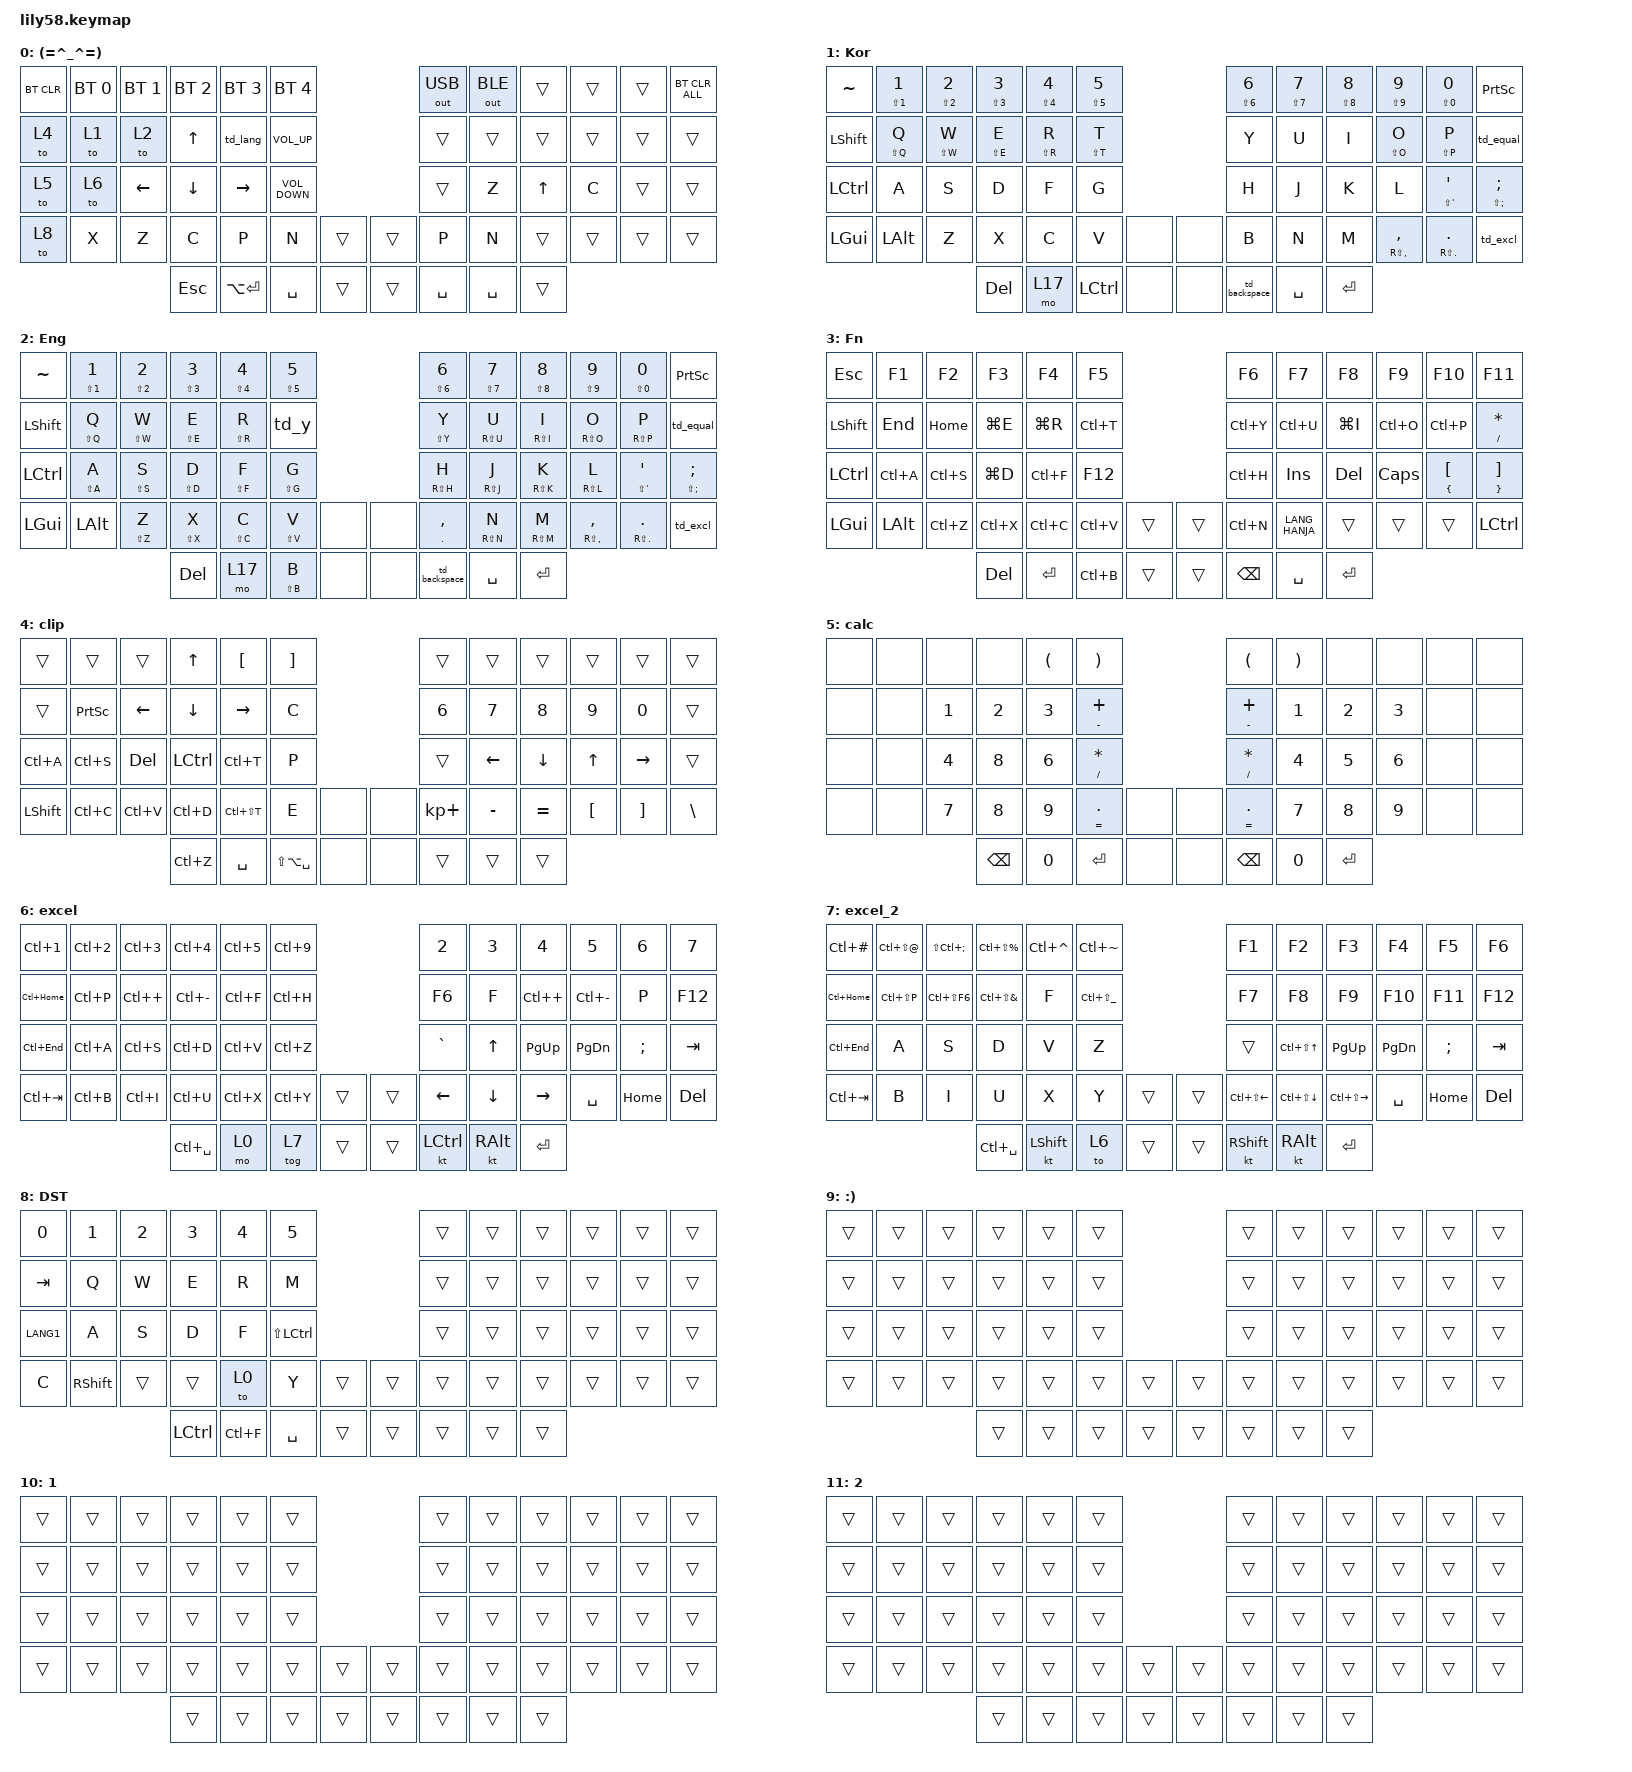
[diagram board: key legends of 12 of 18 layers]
/*
 * Copyright (c) 2020 The ZMK Contributors
 *
 * SPDX-License-Identifier: MIT
 */

#include <behaviors.dtsi>
#include <dt-bindings/zmk/bt.h>
#include <dt-bindings/zmk/keys.h>
#include <dt-bindings/zmk/outputs.h>

/ {
    combos {
        compatible = "zmk,combos";

        ctrl_c {
            bindings = <&kp LC(C)>;
            key-positions = <39 40>;
            timeout-ms = <50>;
        };

        ctrl_v {
            bindings = <&kp LC(V)>;
            key-positions = <39 41>;
            timeout-ms = <50>;
        };

        function {
            bindings = <&sl 3>;
            key-positions = <55 20>;
        };

        calc {
            bindings = <&tog 5>;
            key-positions = <26 28>;
        };

        excel {
            bindings = <&tog 6>;
            key-positions = <52 56>;
        };

        lang {
            bindings = <&kor_layer>;
            key-positions = <28 27>;
            layers = <2 1>;
        };

        egg1 {
            bindings = <&to 10>;
            key-positions = <25 26 15 28 20 21>;
            layers = <2 1>;
        };

        egg2 {
            bindings = <&to 11>;
            key-positions = <40 44 46>;
            layers = <10>;
        };

        egg3 {
            bindings = <&egg3>;
            key-positions = <28 33>;
            layers = <11>;
        };

        egg4 {
            bindings = <&egg4>;
            key-positions = <18>;
            layers = <12>;
        };

        egg_final {
            bindings = <&to 9>;
            key-positions = <1 13 25 37 10 22 34 48>;
            layers = <13>;
        };

        ctrl_del {
            bindings = <&kp LC(DELETE)>;
            key-positions = <27 26>;
            layers = <4>;
        };

        ctrl_layer {
            bindings = <&kp LS(LCTRL)>;
            key-positions = <27 28>;
            layers = <4>;
        };

        th {
            bindings = <&the>;
            key-positions = <17 30>;
            layers = <2>;
        };

        kor_sb {
            bindings = <&kor_sb>;
            key-positions = <17 32 33>;
            layers = <1>;
            timeout-ms = <100>;
        };

        kor_ib {
            bindings = <&kor_ib>;
            key-positions = <27 32 33>;
            layers = <1>;
            timeout-ms = <100>;
        };

        kor_hb {
            bindings = <&kor_hb>;
            key-positions = <29 32 33>;
            layers = <1>;
            timeout-ms = <100>;
        };

        frankenstein {
            bindings = <&frankenstein>;
            key-positions = <29 28 27 30 31 32>;
            layers = <9>;
            timeout-ms = <100>;
            slow-release;
        };

        kor_thx {
            bindings = <&kor_thx>;
            key-positions = <16 32 25>;
            layers = <1>;
        };

        kor_hi {
            bindings = <&kor_hi>;
            key-positions = <26 27 32>;
            layers = <1>;
        };

        base {
            bindings = <&to 0>;
            key-positions = <52 55>;
        };

        clipboard {
            bindings = <&kp LG(V)>;
            key-positions = <40 41>;
        };

        ctrl {
            bindings = <&sl 14>;
            key-positions = <26 27>;
            layers = <1 2>;
        };

        window {
            bindings = <&sl 15>;
            key-positions = <28 26>;
            layers = <1 2>;
        };

        extra {
            bindings = <&sl 16>;
            key-positions = <26 29>;
            layers = <1 2>;
        };

        clipstdio {
            bindings = <&tog 4>;
            key-positions = <52 50>;
        };

        calc2 {
            bindings = <&tog 5>;
            key-positions = <33 32>;
        };

        base2 {
            bindings = <&to 0>;
            key-positions = <15 16>;
        };

        tab {
            bindings = <&kp TAB>;
            key-positions = <15 52>;
        };

        esc {
            bindings = <&kp ESC>;
            key-positions = <27 52>;
        };

        lang1 {
            bindings = <&kp LANG1>;
            key-positions = <28 52>;
        };

        caps {
            bindings = <&kp CAPS>;
            key-positions = <26 52>;
        };
    };

    behaviors {
        td_q: td_q {
            compatible = "zmk,behavior-tap-dance";
            label = "TD_Q";
            #binding-cells = <0>;
            bindings = <&kp Q>, <&kp LS(Q)>;
        };

        td_w: td_w {
            compatible = "zmk,behavior-tap-dance";
            label = "TD_W";
            #binding-cells = <0>;
            bindings = <&kp W>, <&kp LS(W)>;
        };

        td_e: td_e {
            compatible = "zmk,behavior-tap-dance";
            label = "TD_E";
            #binding-cells = <0>;
            bindings = <&kp E>, <&kp LS(E)>;
        };

        td_r: td_r {
            compatible = "zmk,behavior-tap-dance";
            label = "TD_R";
            #binding-cells = <0>;
            bindings = <&kp R>, <&kp LS(R)>;
        };

        td_t: td_t {
            compatible = "zmk,behavior-tap-dance";
            label = "TD_T";
            #binding-cells = <0>;
            bindings = <&kp T>, <&kp LS(T)>;
        };

        td_o: td_o {
            compatible = "zmk,behavior-tap-dance";
            label = "TD_O";
            #binding-cells = <0>;
            bindings = <&kp O>, <&kp LS(O)>;
        };

        td_p: td_p {
            compatible = "zmk,behavior-tap-dance";
            label = "TD_P";
            #binding-cells = <0>;
            bindings = <&kp P>, <&kp LS(P)>;
        };

        to_base: to_base {
            compatible = "zmk,behavior-tap-dance";
            label = "TO_BASE";
            #binding-cells = <0>;
            bindings = <&kp ENTER>, <&to 2>;
        };

        hold_tap: hold_tap {
            compatible = "zmk,behavior-hold-tap";
            label = "HOLD_TAP";
            bindings = <&kp>, <&kp>;

            #binding-cells = <2>;
            tapping-term-ms = <200>;
            flavor = "tap-preferred";
            hold-trigger-key-positions = <0 1 2 3 4 5 13 14 15 16 17 25 26 27 28 29 12 13 14 15 16 17 24 25 26 27 28 29 36 37 38 39 40 41 50 51 52 6 7 8 9 10 11 18 19 20 21 22 23 30 31 32 33 34 35 44 45 46 47 48 49 55 56 57>;
        };

        td_csh: td_csh {
            compatible = "zmk,behavior-tap-dance";
            label = "TD_CSH";
            #binding-cells = <0>;
            bindings = <&kp LEFT_SHIFT>, <&kp LC(LEFT_SHIFT)>;
        };

        egg3: egg3 {
            compatible = "zmk,behavior-tap-dance";
            label = "EGG3";
            #binding-cells = <0>;
            bindings = <&none>, <&to 12>;
        };

        egg4: egg4 {
            compatible = "zmk,behavior-tap-dance";
            label = "EGG4";
            #binding-cells = <0>;
            bindings = <&none>, <&none>, <&none>, <&none>, <&ht_layer 13 0>;
        };

        ht_layer: ht_layer {
            compatible = "zmk,behavior-hold-tap";
            label = "HT_LAYER";
            bindings = <&to>, <&none>;

            #binding-cells = <2>;
            tapping-term-ms = <200>;
            flavor = "tap-preferred";
            hold-trigger-key-positions = <0 1 2 3 4 5 6 7 8 9 10 11 12 13 14 15 16 17 18 19 20 21 22 23 24 25 26 27 28 29 30 31 32 33 34 35 36 37 38 39 40 41 42 43 44 45 46 47 48 49 50 51 52 53 54 55 56 57>;
        };

        td_y: td_y {
            compatible = "zmk,behavior-tap-dance";
            label = "TD_Y";
            #binding-cells = <0>;
            bindings = <&hold_tap LS(T) T>, <&hold_tap RS(Y) Y>;

            tapping-term-ms = <250>;
        };

        td_excl: td_excl {
            compatible = "zmk,behavior-tap-dance";
            label = "TD_EXCL";
            #binding-cells = <0>;
            bindings = <&kp QUESTION>, <&kp EXCL>;
        };

        td_lang: td_lang {
            compatible = "zmk,behavior-tap-dance";
            label = "TD_LANG";
            #binding-cells = <0>;
            bindings = <&kp LANGUAGE_1>, <&kp LANG2>;
        };

        td_backspace: td_backspace {
            compatible = "zmk,behavior-tap-dance";
            label = "TD_BACKSPACE";
            #binding-cells = <0>;
            bindings = <&kp BACKSPACE>, <&kp LC(BACKSPACE)>;
        };

        td_equal: td_equal {
            compatible = "zmk,behavior-tap-dance";
            label = "TD_EQUAL";
            #binding-cells = <0>;
            bindings = <&hold_tap LS(MINUS) MINUS>, <&hold_tap LS(EQUAL) EQUAL>;
        };
    };

    macros {
        kor_layer: eng_kor {
            compatible = "zmk,behavior-macro";
            #binding-cells = <0>;
            bindings = <&kp LANG1 &tog 2>;
            label = "ENG_KOR";
        };

        the: the {
            compatible = "zmk,behavior-macro";
            #binding-cells = <0>;
            bindings = <&kp T &kp H>;
            label = "THE";
        };

        kor_sb: kor_sb {
            compatible = "zmk,behavior-macro";
            #binding-cells = <0>;
            bindings = <&kp T &kp M &kp Q &kp S &kp L &kp E &kp K &kp DOT>;
            label = "KOR_SB";
        };

        kor_ib: kor_ind {
            compatible = "zmk,behavior-macro";
            #binding-cells = <0>;
            bindings = <&kp D &kp L &kp Q &kp S &kp L &kp E &kp K &kp DOT>;
            label = "KOR_IND";
        };

        kor_hb: kor_hb {
            compatible = "zmk,behavior-macro";
            #binding-cells = <0>;
            bindings = <&kp G &kp K &kp Q &kp S &kp L &kp E &kp K &kp DOT>;
            label = "KOR_HB";
        };

        frankenstein: frankenstein {
            compatible = "zmk,behavior-macro";
            #binding-cells = <0>;
            bindings = <&kp D &kp N &kp L &kp E &kp O &kp G &kp K &kp S &kp SPACE &kp T &kp O &kp D &kp A &kp U &kp D &kp C &kp K &kp D &kp W &kp H &kp D &kp M &kp L &kp SPACE &kp D &kp U &kp R &kp T &kp K &kp R &kp K &kp SPACE &kp T &kp L &kp W &kp K &kp R &kp E &kp H &kp L &kp S &kp E &kp K>;
            label = "FRANKENSTEIN";
        };

        kor_not_only: kor_not_only {
            compatible = "zmk,behavior-macro";
            #binding-cells = <0>;
            bindings = <&kp LS(Q) &kp N &kp S &kp SPACE &kp D &kp K &kp S &kp L &kp F &kp K>;
            label = "KOR_NOT_ONLY";
        };

        kor_thx: kor_thx {
            compatible = "zmk,behavior-macro";
            #binding-cells = <0>;
            bindings = <&kp R &kp K &kp A &kp T &kp K &kp G &kp K &kp Q &kp S &kp L &kp E &kp K>;
            label = "KOR_THX";
        };

        kor_hi: kor_hi {
            compatible = "zmk,behavior-macro";
            #binding-cells = <0>;
            bindings = <&kp D &kp K &kp S &kp S &kp U &kp D &kp G &kp K &kp T &kp P &kp D &kp Y>;
            label = "KOR_HI";
        };
    };

    keymap {
        compatible = "zmk,keymap";

        base {
            bindings = <
&bt BT_CLR  &bt BT_SEL 0  &bt BT_SEL 1    &bt BT_SEL 2    &bt BT_SEL 3     &bt BT_SEL 4                         &out OUT_USB  &out OUT_BLE  &trans        &trans  &trans  &bt BT_CLR_ALL
&to 4       &to 1         &to 2           &kp UP_ARROW    &td_lang         &kp C_VOLUME_UP                      &trans        &trans        &trans        &trans  &trans  &trans
&to 5       &to 6         &kp LEFT_ARROW  &kp DOWN_ARROW  &kp RIGHT_ARROW  &kp C_VOLUME_DOWN                    &trans        &kp Z         &kp UP_ARROW  &kp C   &trans  &trans
&to 8       &kp X         &kp Z           &kp C           &kp P            &kp N              &trans    &trans  &kp P         &kp N         &trans        &trans  &trans  &trans
                                          &kp ESC         &kp LA(ENTER)    &kp SPACE          &trans    &trans  &kp SPACE     &kp SPACE     &trans
            >;

            label = "(=^_^=)";
        };

        KOR {
            display-name = "Kor";
            bindings = <
&kp TILDE       &hold_tap LS(N1) NUMBER_1  &hold_tap LS(N2) NUMBER_2  &hold_tap LS(N3) NUMBER_3  &hold_tap LS(N4) NUMBER_4  &hold_tap LS(N5) N5                  &hold_tap LS(N6) NUMBER_6  &hold_tap LS(N7) N7  &hold_tap LS(N8) N8  &hold_tap LS(N9) N9        &hold_tap LS(N0) N0          &kp PRINTSCREEN
&kp LEFT_SHIFT  &hold_tap LS(Q) Q          &hold_tap LS(W) W          &hold_tap LS(E) E          &hold_tap LS(R) R          &hold_tap LS(T) T                    &kp Y                      &kp U                &kp I                &hold_tap LS(O) O          &hold_tap LS(P) P            &td_equal
&kp LCTRL       &kp A                      &kp S                      &kp D                      &kp F                      &kp G                                &kp H                      &kp J                &kp K                &kp L                      &hold_tap LS(APOS) APOS      &hold_tap LS(SEMICOLON) SEMICOLON
&kp LEFT_GUI    &kp LEFT_ALT               &kp Z                      &kp X                      &kp C                      &kp V                &none    &none  &kp B                      &kp N                &kp M                &hold_tap RS(COMMA) COMMA  &hold_tap RS(PERIOD) PERIOD  &td_excl
                                                                      &kp DEL                    &mo 17                     &kp LCTRL            &none    &none  &td_backspace              &kp SPACE            &kp ENTER
            >;
        };

        ENG {
            // ------------------------------------------------------------------------------------------------------------
            // |  ESC  |  1  |  2  |  3   |  4   |  5   |                   |  6   |  7    |  8    |  9   |   0   |   `   |
            // |  TAB  |  Q  |  W  |  E   |  R   |  T   |                   |  Y   |  U    |  I    |  O   |   P   |   -   |
            // |  CTRL |  A  |  S  |  D   |  F   |  G   |                   |  H   |  J    |  K    |  L   |   ;   |   '   |
            // | SHIFT |  Z  |  X  |  C   |  V   |  B   |  n/a   |  |  n/a  |  N   |  M    |  ,    |  .   |   /   | SHIFT |
            //                     | GUI  | LOWER| SPACE|  n/a   |  |  n/a  | ENTER| RAISE | BSPC  |
            // Note: Silakka54 has 54 keys - the 4 positions marked n/a are not present (inner thumb + encoder positions)

            display-name = "Eng";
            bindings = <
&kp TILDE       &hold_tap LS(N1) NUMBER_1  &hold_tap LS(N2) NUMBER_2  &hold_tap LS(N3) NUMBER_3  &hold_tap LS(N4) NUMBER_4  &hold_tap LS(N5) N5                  &hold_tap LS(N6) NUMBER_6  &hold_tap LS(N7) N7  &hold_tap LS(N8) N8  &hold_tap LS(N9) N9        &hold_tap LS(N0) N0          &kp PRINTSCREEN
&kp LEFT_SHIFT  &hold_tap LS(Q) Q          &hold_tap LS(W) W          &hold_tap LS(E) E          &hold_tap LS(R) R          &td_y                                &hold_tap LS(Y) Y          &hold_tap RS(U) U    &hold_tap RS(I) I    &hold_tap RS(O) O          &hold_tap RS(P) P            &td_equal
&kp LCTRL       &hold_tap LS(A) A          &hold_tap LS(S) S          &hold_tap LS(D) D          &hold_tap LS(F) F          &hold_tap LS(G) G                    &hold_tap RS(H) H          &hold_tap RS(J) J    &hold_tap RS(K) K    &hold_tap RS(L) L          &hold_tap LS(APOS) APOS      &hold_tap LS(SEMI) SEMI
&kp LGUI        &kp LEFT_ALT               &hold_tap LS(Z) Z          &hold_tap LS(X) X          &hold_tap LS(C) C          &hold_tap LS(V) V    &none    &none  &hold_tap PERIOD COMMA     &hold_tap RS(N) N    &hold_tap RS(M) M    &hold_tap RS(COMMA) COMMA  &hold_tap RS(PERIOD) PERIOD  &td_excl
                                                                      &kp DEL                    &mo 17                     &hold_tap LS(B) B    &none    &none  &td_backspace              &kp SPACE            &kp ENTER
            >;
        };

        function {
            bindings = <
&kp ESC         &kp F1     &kp F2     &kp F3      &kp F4     &kp F5                       &kp F6     &kp F7          &kp F8     &kp F9     &kp F10                            &kp F11
&kp LEFT_SHIFT  &kp END    &kp HOME   &kp LG(E)   &kp LG(R)  &kp LC(T)                    &kp LC(Y)  &kp LC(U)       &kp LG(I)  &kp LC(O)  &kp LC(P)                          &hold_tap SLASH ASTERISK
&kp LCTRL       &kp LC(A)  &kp LC(S)  &kp LG(D)   &kp LC(F)  &kp F12                      &kp LC(H)  &kp INSERT      &kp DEL    &kp CAPS   &hold_tap LEFT_BRACE LEFT_BRACKET  &hold_tap RIGHT_BRACE RIGHT_BRACKET
&kp LGUI        &kp LALT   &kp LC(Z)  &kp LC(X)   &kp LC(C)  &kp LC(V)  &trans    &trans  &kp LC(N)  &kp LANG_HANJA  &trans     &trans     &trans                             &kp LCTRL
                                      &kp DELETE  &kp ENTER  &kp LC(B)  &trans    &trans  &kp BSPC   &kp SPACE       &kp ENTER
            >;

            label = "Fn";
        };

        clip_studio {
            // ------------------------------------------------------------------------------------------------------------
            // |       |     |     |      |      |      |                   |      |       |       |      |       |       |
            // |   `   |  1  |  2  |  3   |  4   |  5   |                   |  6   |   7   |   8   |  9   |   0   |       |
            // |   F1  |  F2 |  F3 |  F4  |  F5  |  F6  |                   |      |   <-  |   v   |  ^   |  ->   |       |
            // |   F7  |  F8 |  F9 |  F10 |  F11 |  F12 |  n/a   |  |  n/a  |  +   |   -   |   =   |  [   |   ]   |   \   |
            //                     |      |      |      |  n/a   |  |  n/a  |      |       |       |

            display-name = "clip";
            bindings = <
&trans     &trans           &trans          &kp UP_ARROW    &kp LBKT         &kp RBKT                           &trans       &trans     &trans     &trans    &trans     &trans
&trans     &kp PRINTSCREEN  &kp LEFT_ARROW  &kp DOWN_ARROW  &kp RIGHT_ARROW  &kp C                              &kp N6       &kp N7     &kp N8     &kp N9    &kp N0     &trans
&kp LC(A)  &kp LC(S)        &kp DELETE      &kp LCTRL       &kp LC(T)        &kp P                              &trans       &kp LEFT   &kp DOWN   &kp UP    &kp RIGHT  &trans
&kp LSHFT  &kp LC(C)        &kp LC(V)       &kp LC(D)       &kp LC(LS(T))    &kp E              &none    &none  &kp KP_PLUS  &kp MINUS  &kp EQUAL  &kp LBKT  &kp RBKT   &kp BSLH
                                            &kp LC(Z)       &kp SPACE        &kp LS(LA(SPACE))  &none    &none  &trans       &trans     &trans
            >;
        };

        calc {
            display-name = "calc";
            bindings = <
&none  &none  &none   &none     &kp LEFT_PARENTHESIS  &kp RIGHT_PARENTHESIS                   &kp LEFT_PARENTHESIS      &kp RIGHT_PARENTHESIS  &none      &none   &none  &none
&none  &none  &kp N1  &kp N2    &kp N3                &hold_tap MINUS PLUS                    &hold_tap MINUS PLUS      &kp N1                 &kp N2     &kp N3  &none  &none
&none  &none  &kp N4  &kp N8    &kp N6                &hold_tap SLASH ASTRK                   &hold_tap SLASH ASTERISK  &kp N4                 &kp N5     &kp N6  &none  &none
&none  &none  &kp N7  &kp N8    &kp N9                &hold_tap EQUAL PERIOD  &none    &none  &hold_tap EQUAL PERIOD    &kp N7                 &kp N8     &kp N9  &none  &none
                      &kp BSPC  &kp N0                &kp ENTER               &none    &none  &kp BSPC                  &kp N0                 &kp ENTER
            >;
        };

        excel {
            bindings = <
&kp LC(N1)    &kp LC(N2)  &kp LC(N3)    &kp LC(N4)     &kp LC(N5)  &kp LC(N9)                    &kp N2     &kp N3         &kp N4        &kp N5         &kp N6    &kp N7
&kp LC(HOME)  &kp LC(P)   &kp LC(PLUS)  &kp LC(MINUS)  &kp LC(F)   &kp LC(H)                     &kp F6     &kp F          &kp LC(PLUS)  &kp LC(MINUS)  &kp P     &kp F12
&kp LC(END)   &kp LC(A)   &kp LC(S)     &kp LC(D)      &kp LC(V)   &kp LC(Z)                     &kp GRAVE  &kp UP         &kp PAGE_UP   &kp PAGE_DOWN  &kp SEMI  &kp TAB
&kp LC(TAB)   &kp LC(B)   &kp LC(I)     &kp LC(U)      &kp LC(X)   &kp LC(Y)   &trans    &trans  &kp LEFT   &kp DOWN       &kp RIGHT     &kp SPACE      &kp HOME  &kp DELETE
                                        &kp LC(SPACE)  &mo 0       &tog 7      &trans    &trans  &kt LCTRL  &kt RIGHT_ALT  &kp ENTER
            >;

            label = "excel";
        };

        ctrl_shift {
            bindings = <
&kp LC(HASH)  &kp LC(LS(AT_SIGN))  &kp LS(LC(SEMICOLON))  &kp LC(LS(PERCENT))    &kp LC(CARET)  &kp LC(TILDE)                             &kp F1            &kp F2            &kp F3             &kp F4         &kp F5    &kp F6
&kp LC(HOME)  &kp LC(LS(P))        &kp LC(LS(F6))         &kp LC(LS(AMPERSAND))  &kp F          &kp LC(LS(UNDERSCORE))                    &kp F7            &kp F8            &kp F9             &kp F10        &kp F11   &kp F12
&kp LC(END)   &kp A                &kp S                  &kp D                  &kp V          &kp Z                                     &trans            &kp LC(LS(UP))    &kp PAGE_UP        &kp PAGE_DOWN  &kp SEMI  &kp TAB
&kp LC(TAB)   &kp B                &kp I                  &kp U                  &kp X          &kp Y                   &trans    &trans  &kp LC(LS(LEFT))  &kp LC(LS(DOWN))  &kp LC(LS(RIGHT))  &kp SPACE      &kp HOME  &kp DELETE
                                                          &kp LC(SPACE)          &kt LSHFT      &to 6                   &trans    &trans  &kt RSHFT         &kt RIGHT_ALT     &kp ENTER
            >;

            label = "excel_2";
        };

        dst {
            bindings = <
&kp N0     &kp N1     &kp N2  &kp N3     &kp N4     &kp N5                           &trans  &trans  &trans  &trans  &trans  &trans
&kp TAB    &kp Q      &kp W   &kp E      &kp R      &kp M                            &trans  &trans  &trans  &trans  &trans  &trans
&kp LANG1  &kp A      &kp S   &kp D      &kp F      &kp LS(LCTRL)                    &trans  &trans  &trans  &trans  &trans  &trans
&kp C      &kp RSHFT  &trans  &trans     &to 0      &kp Y          &trans    &trans  &trans  &trans  &trans  &trans  &trans  &trans
                              &kp LCTRL  &kp LC(F)  &kp SPACE      &trans    &trans  &trans  &trans  &trans
            >;

            label = "DST";
        };

        welcome {
            bindings = <
&trans  &trans  &trans  &trans  &trans  &trans                    &trans  &trans  &trans  &trans  &trans  &trans
&trans  &trans  &trans  &trans  &trans  &trans                    &trans  &trans  &trans  &trans  &trans  &trans
&trans  &trans  &trans  &trans  &trans  &trans                    &trans  &trans  &trans  &trans  &trans  &trans
&trans  &trans  &trans  &trans  &trans  &trans  &trans    &trans  &trans  &trans  &trans  &trans  &trans  &trans
                        &trans  &trans  &trans  &trans    &trans  &trans  &trans  &trans
            >;

            label = ":)";
        };

        egg1 {
            bindings = <
&trans  &trans  &trans  &trans  &trans  &trans                    &trans  &trans  &trans  &trans  &trans  &trans
&trans  &trans  &trans  &trans  &trans  &trans                    &trans  &trans  &trans  &trans  &trans  &trans
&trans  &trans  &trans  &trans  &trans  &trans                    &trans  &trans  &trans  &trans  &trans  &trans
&trans  &trans  &trans  &trans  &trans  &trans  &trans    &trans  &trans  &trans  &trans  &trans  &trans  &trans
                        &trans  &trans  &trans  &trans    &trans  &trans  &trans  &trans
            >;

            label = "1";
        };

        egg2 {
            bindings = <
&trans  &trans  &trans  &trans  &trans  &trans                    &trans  &trans  &trans  &trans  &trans  &trans
&trans  &trans  &trans  &trans  &trans  &trans                    &trans  &trans  &trans  &trans  &trans  &trans
&trans  &trans  &trans  &trans  &trans  &trans                    &trans  &trans  &trans  &trans  &trans  &trans
&trans  &trans  &trans  &trans  &trans  &trans  &trans    &trans  &trans  &trans  &trans  &trans  &trans  &trans
                        &trans  &trans  &trans  &trans    &trans  &trans  &trans  &trans
            >;

            label = "2";
        };

        egg3 {
            bindings = <
&trans  &trans  &trans  &trans  &trans  &trans                    &trans  &trans  &trans  &trans  &trans  &trans
&trans  &trans  &trans  &trans  &trans  &trans                    &trans  &trans  &trans  &trans  &trans  &trans
&trans  &trans  &trans  &trans  &trans  &trans                    &trans  &trans  &trans  &trans  &trans  &trans
&trans  &trans  &trans  &trans  &trans  &trans  &trans    &trans  &trans  &trans  &trans  &trans  &trans  &trans
                        &trans  &trans  &trans  &trans    &trans  &trans  &trans  &trans
            >;

            label = "3";
        };

        egg4 {
            bindings = <
&trans  &trans  &trans  &trans  &trans  &trans                    &trans  &trans  &trans  &trans  &trans  &trans
&trans  &trans  &trans  &trans  &trans  &trans                    &trans  &trans  &trans  &trans  &trans  &trans
&trans  &trans  &trans  &trans  &trans  &trans                    &trans  &trans  &trans  &trans  &trans  &trans
&trans  &trans  &trans  &trans  &trans  &trans  &trans    &trans  &trans  &trans  &trans  &trans  &trans  &trans
                        &trans  &trans  &trans  &trans    &trans  &trans  &trans  &trans
            >;

            label = "4";
        };

        ctrl {
            bindings = <
&trans          &kp LC(D)    &kp LC(T)     &kp LC(B)           &kp LC(I)            &kp LC(U)                    &trans  &trans  &trans  &trans  &trans  &trans
&kp LC(TAB)     &kp LC(END)  &kp LC(HOME)  &kp LC(LEFT_ARROW)  &kp LC(RIGHT_ARROW)  &kp LC(P)                    &trans  &trans  &trans  &trans  &trans  &trans
&kp LC(ESCAPE)  &kp LC(S)    &kp LC(A)     &kp DEL             &kp LC(F)            &kp LC(H)                    &trans  &trans  &trans  &trans  &trans  &trans
&kp LC(O)       &kp LC(N)    &kp LC(Y)     &kp LC(X)           &kp LC(C)            &kp LC(V)  &trans    &trans  &trans  &trans  &trans  &trans  &trans  &trans
                                           &kp LC(Z)           &kp LC(LEFT_ALT)     &sk LSHFT  &trans    &trans  &trans  &trans  &trans
            >;

            label = "ctrl";
        };

        window {
            bindings = <
&kp LG(F4)  &trans               &trans              &kp LG(UP_ARROW)    &trans               &trans                       &trans  &trans  &trans  &trans  &trans  &trans
&trans      &kp LG(TAB)          &kp LG(LEFT_ARROW)  &kp LG(DOWN_ARROW)  &kp LG(RIGHT_ARROW)  &kp LG(R)                    &trans  &trans  &trans  &trans  &trans  &trans
&trans      &kp LG(PRINTSCREEN)  &kp LG(D)           &kp LG(E)           &kp LG(I)            &kp LG(L)                    &trans  &trans  &trans  &trans  &trans  &trans
&trans      &trans               &kp LG(PERIOD)      &kp LG(P)           &kp LG(S)            &kp LG(V)  &trans    &trans  &trans  &trans  &trans  &trans  &trans  &trans
                                                     &sk LEFT_ALT        &sk LCTRL            &sk LSHFT  &trans    &trans  &trans  &trans  &trans
            >;

            label = "win";
        };

        extra {
            bindings = <
&trans      &trans         &trans         &trans  &trans       &trans                     &trans  &trans  &trans  &trans  &trans  &trans
&kp LA(F4)  &kp F3         &kp F4         &kp F5  &kp F6       &kp F10                    &trans  &trans  &trans  &trans  &trans  &trans
&trans      &kp LA(SPACE)  &kp LA(ENTER)  &kp F2  &kp LA(TAB)  &trans                     &trans  &trans  &trans  &trans  &trans  &trans
&trans      &trans         &trans         &trans  &trans       &trans   &trans    &trans  &trans  &trans  &trans  &trans  &trans  &trans
                                          &trans  &trans       &trans   &trans    &trans  &trans  &trans  &trans
            >;

            label = "esc";
        };

        arrow {
            bindings = <
&trans  &trans  &trans          &trans          &trans           &trans                    &trans  &trans  &trans  &trans  &trans  &trans
&trans  &trans  &kp ESCAPE      &kp UP_ARROW    &kp F2           &trans                    &trans  &trans  &trans  &trans  &trans  &trans
&trans  &trans  &kp LEFT_ARROW  &kp DOWN_ARROW  &kp RIGHT_ARROW  &trans                    &trans  &trans  &trans  &trans  &trans  &trans
&trans  &trans  &trans          &trans          &trans           &trans  &trans    &trans  &trans  &trans  &trans  &trans  &trans  &trans
                                &trans          &trans           &trans  &trans    &trans  &trans  &trans  &trans
            >;

            label = "arrow";
        };
    };

    conditional_layers { compatible = "zmk,conditional-layers"; };
};
